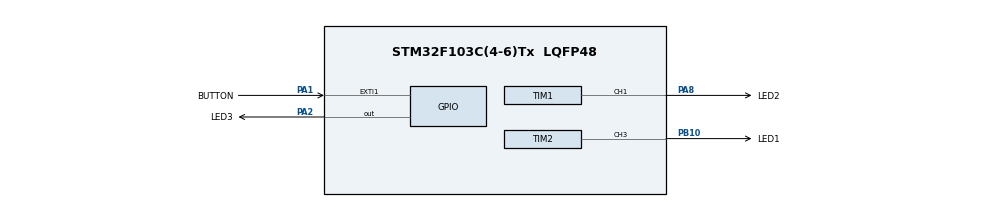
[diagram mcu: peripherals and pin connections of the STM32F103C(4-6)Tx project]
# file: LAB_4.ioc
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Mcu.Family=STM32F1
Mcu.Name=STM32F103C(4-6)Tx
Mcu.Package=LQFP48
NVIC.EXTI1_IRQn=true\:0\:0\:false\:true\:true\:1\:true\:true
NVIC.PriorityGroup=NVIC_PRIORITYGROUP_4
PA1.GPIO_Label=BUTTON
PA1.Signal=GPXTI1
PA2.GPIO_Label=LED3
PA2.Signal=GPIO_Output
PA8.GPIO_Label=LED2
PA8.Signal=S_TIM1_CH1
PB10.GPIO_Label=LED1
PB10.Signal=S_TIM2_CH3
ProjectManager.HeapSize=0x200
ProjectManager.StackSize=0x400
ProjectManager.TargetToolchain=STM32CubeIDE
RCC.APB1Freq_Value=8000000
RCC.APB2Freq_Value=8000000
SH.S_TIM1_CH1.0=TIM1_CH1,PWM Generation1 CH1
SH.S_TIM2_CH3.0=TIM2_CH3,PWM Generation3 CH3
TIM1.Channel-PWM\ Generation1\ CH1=TIM_CHANNEL_1
TIM1.ClockDivision=TIM_CLOCKDIVISION_DIV4
TIM1.Period=400
TIM1.Prescaler=8000
TIM1.Pulse-PWM\ Generation1\ CH1=200
TIM2.Channel-PWM\ Generation3\ CH3=TIM_CHANNEL_3
TIM2.ClockDivision=TIM_CLOCKDIVISION_DIV4
TIM2.Period=800
TIM2.Prescaler=8000
TIM2.Pulse-PWM\ Generation3\ CH3=200
VP_SYS_VS_ND.Mode=No_Debug
VP_TIM1_VS_ClockSourceINT.Mode=Internal
VP_TIM2_VS_ClockSourceINT.Mode=Internal
board=custom

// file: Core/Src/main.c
/* USER CODE BEGIN Header */
/**
  ******************************************************************************
  * @file           : main.c
  * @brief          : Main program body
  ******************************************************************************
  * @attention
  *
  * <h2><center>&copy; Copyright (c) 2021 STMicroelectronics.
  * All rights reserved.</center></h2>
  *
  * This software component is licensed by ST under BSD 3-Clause license,
  * the "License"; You may not use this file except in compliance with the
  * License. You may obtain a copy of the License at:
  *                        opensource.org/licenses/BSD-3-Clause
  *
  ******************************************************************************
  */
/* USER CODE END Header */
#include "main.h"

TIM_HandleTypeDef htim1;
TIM_HandleTypeDef htim2;

void SystemClock_Config(void);
static void MX_GPIO_Init(void);
static void MX_TIM1_Init(void);
static void MX_TIM2_Init(void);
static void MX_NVIC_Init(void);

int main(void)
{

  /* MCU Configuration--------------------------------------------------------*/

  /* Reset of all peripherals, Initializes the Flash interface and the Systick. */
  HAL_Init();

  /* Configure the system clock */
  SystemClock_Config();

  /* Initialize all configured peripherals */
  MX_GPIO_Init();
  MX_TIM1_Init();
  MX_TIM2_Init();

  /* Initialize interrupts */
  MX_NVIC_Init();
  /* USER CODE BEGIN 2 */
  HAL_TIM_PWM_Start(&htim1, TIM_CHANNEL_1);
  HAL_TIM_PWM_Start(&htim2, TIM_CHANNEL_3);
  /* USER CODE END 2 */

  /* Infinite loop */
  /* USER CODE BEGIN WHILE */
  while (1)
  {
	  HAL_GPIO_TogglePin(LED3_GPIO_Port, LED3_Pin);
	  HAL_Delay(300);
    /* USER CODE END WHILE */

  }
}

void SystemClock_Config(void)
{
  RCC_OscInitTypeDef RCC_OscInitStruct = {0};
  RCC_ClkInitTypeDef RCC_ClkInitStruct = {0};

  /** Initializes the RCC Oscillators according to the specified parameters
  * in the RCC_OscInitTypeDef structure.
  */
  RCC_OscInitStruct.OscillatorType = RCC_OSCILLATORTYPE_HSI;
  RCC_OscInitStruct.HSIState = RCC_HSI_ON;
  RCC_OscInitStruct.HSICalibrationValue = RCC_HSICALIBRATION_DEFAULT;
  RCC_OscInitStruct.PLL.PLLState = RCC_PLL_NONE;
  if (HAL_RCC_OscConfig(&RCC_OscInitStruct) != HAL_OK)
  {
    Error_Handler();
  }
  /** Initializes the CPU, AHB and APB buses clocks
  */
  RCC_ClkInitStruct.ClockType = RCC_CLOCKTYPE_HCLK|RCC_CLOCKTYPE_SYSCLK
                              |RCC_CLOCKTYPE_PCLK1|RCC_CLOCKTYPE_PCLK2;
  RCC_ClkInitStruct.SYSCLKSource = RCC_SYSCLKSOURCE_HSI;
  RCC_ClkInitStruct.AHBCLKDivider = RCC_SYSCLK_DIV1;
  RCC_ClkInitStruct.APB1CLKDivider = RCC_HCLK_DIV1;
  RCC_ClkInitStruct.APB2CLKDivider = RCC_HCLK_DIV1;

  if (HAL_RCC_ClockConfig(&RCC_ClkInitStruct, FLASH_LATENCY_0) != HAL_OK)
  {
    Error_Handler();
  }
}

/**
  * @brief NVIC Configuration.
  * @retval None
  */
static void MX_NVIC_Init(void)
{
  /* EXTI1_IRQn interrupt configuration */
  HAL_NVIC_SetPriority(EXTI1_IRQn, 0, 0);
  HAL_NVIC_EnableIRQ(EXTI1_IRQn);
}

static void MX_TIM1_Init(void)
{

  TIM_ClockConfigTypeDef sClockSourceConfig = {0};
  TIM_MasterConfigTypeDef sMasterConfig = {0};
  TIM_OC_InitTypeDef sConfigOC = {0};
  TIM_BreakDeadTimeConfigTypeDef sBreakDeadTimeConfig = {0};

  htim1.Instance = TIM1;
  htim1.Init.Prescaler = 8000;
  htim1.Init.CounterMode = TIM_COUNTERMODE_UP;
  htim1.Init.Period = 400;
  htim1.Init.ClockDivision = TIM_CLOCKDIVISION_DIV4;
  htim1.Init.RepetitionCounter = 0;
  htim1.Init.AutoReloadPreload = TIM_AUTORELOAD_PRELOAD_DISABLE;
  if (HAL_TIM_Base_Init(&htim1) != HAL_OK)
  {
    Error_Handler();
  }
  sClockSourceConfig.ClockSource = TIM_CLOCKSOURCE_INTERNAL;
  if (HAL_TIM_ConfigClockSource(&htim1, &sClockSourceConfig) != HAL_OK)
  {
    Error_Handler();
  }
  if (HAL_TIM_PWM_Init(&htim1) != HAL_OK)
  {
    Error_Handler();
  }
  sMasterConfig.MasterOutputTrigger = TIM_TRGO_RESET;
  sMasterConfig.MasterSlaveMode = TIM_MASTERSLAVEMODE_DISABLE;
  if (HAL_TIMEx_MasterConfigSynchronization(&htim1, &sMasterConfig) != HAL_OK)
  {
    Error_Handler();
  }
  sConfigOC.OCMode = TIM_OCMODE_PWM1;
  sConfigOC.Pulse = 200;
  sConfigOC.OCPolarity = TIM_OCPOLARITY_HIGH;
  sConfigOC.OCNPolarity = TIM_OCNPOLARITY_HIGH;
  sConfigOC.OCFastMode = TIM_OCFAST_DISABLE;
  sConfigOC.OCIdleState = TIM_OCIDLESTATE_RESET;
  sConfigOC.OCNIdleState = TIM_OCNIDLESTATE_RESET;
  if (HAL_TIM_PWM_ConfigChannel(&htim1, &sConfigOC, TIM_CHANNEL_1) != HAL_OK)
  {
    Error_Handler();
  }
  sBreakDeadTimeConfig.OffStateRunMode = TIM_OSSR_DISABLE;
  sBreakDeadTimeConfig.OffStateIDLEMode = TIM_OSSI_DISABLE;
  sBreakDeadTimeConfig.LockLevel = TIM_LOCKLEVEL_OFF;
  sBreakDeadTimeConfig.DeadTime = 0;
  sBreakDeadTimeConfig.BreakState = TIM_BREAK_DISABLE;
  sBreakDeadTimeConfig.BreakPolarity = TIM_BREAKPOLARITY_HIGH;
  sBreakDeadTimeConfig.AutomaticOutput = TIM_AUTOMATICOUTPUT_DISABLE;
  if (HAL_TIMEx_ConfigBreakDeadTime(&htim1, &sBreakDeadTimeConfig) != HAL_OK)
  {
    Error_Handler();
  }
  HAL_TIM_MspPostInit(&htim1);

}

static void MX_TIM2_Init(void)
{

  TIM_ClockConfigTypeDef sClockSourceConfig = {0};
  TIM_MasterConfigTypeDef sMasterConfig = {0};
  TIM_OC_InitTypeDef sConfigOC = {0};

  htim2.Instance = TIM2;
  htim2.Init.Prescaler = 8000;
  htim2.Init.CounterMode = TIM_COUNTERMODE_UP;
  htim2.Init.Period = 800;
  htim2.Init.ClockDivision = TIM_CLOCKDIVISION_DIV4;
  htim2.Init.AutoReloadPreload = TIM_AUTORELOAD_PRELOAD_DISABLE;
  if (HAL_TIM_Base_Init(&htim2) != HAL_OK)
  {
    Error_Handler();
  }
  sClockSourceConfig.ClockSource = TIM_CLOCKSOURCE_INTERNAL;
  if (HAL_TIM_ConfigClockSource(&htim2, &sClockSourceConfig) != HAL_OK)
  {
    Error_Handler();
  }
  if (HAL_TIM_PWM_Init(&htim2) != HAL_OK)
  {
    Error_Handler();
  }
  sMasterConfig.MasterOutputTrigger = TIM_TRGO_RESET;
  sMasterConfig.MasterSlaveMode = TIM_MASTERSLAVEMODE_DISABLE;
  if (HAL_TIMEx_MasterConfigSynchronization(&htim2, &sMasterConfig) != HAL_OK)
  {
    Error_Handler();
  }
  sConfigOC.OCMode = TIM_OCMODE_PWM1;
  sConfigOC.Pulse = 200;
  sConfigOC.OCPolarity = TIM_OCPOLARITY_HIGH;
  sConfigOC.OCFastMode = TIM_OCFAST_DISABLE;
  if (HAL_TIM_PWM_ConfigChannel(&htim2, &sConfigOC, TIM_CHANNEL_3) != HAL_OK)
  {
    Error_Handler();
  }
  HAL_TIM_MspPostInit(&htim2);

}

static void MX_GPIO_Init(void)
{
  GPIO_InitTypeDef GPIO_InitStruct = {0};

  /* GPIO Ports Clock Enable */
  __HAL_RCC_GPIOA_CLK_ENABLE();
  __HAL_RCC_GPIOB_CLK_ENABLE();

  /*Configure GPIO pin Output Level */
  HAL_GPIO_WritePin(LED3_GPIO_Port, LED3_Pin, GPIO_PIN_RESET);

  /*Configure GPIO pin : BUTTON_Pin */
  GPIO_InitStruct.Pin = BUTTON_Pin;
  GPIO_InitStruct.Mode = GPIO_MODE_IT_RISING;
  GPIO_InitStruct.Pull = GPIO_NOPULL;
  HAL_GPIO_Init(BUTTON_GPIO_Port, &GPIO_InitStruct);

  /*Configure GPIO pin : LED3_Pin */
  GPIO_InitStruct.Pin = LED3_Pin;
  GPIO_InitStruct.Mode = GPIO_MODE_OUTPUT_PP;
  GPIO_InitStruct.Pull = GPIO_NOPULL;
  GPIO_InitStruct.Speed = GPIO_SPEED_FREQ_LOW;
  HAL_GPIO_Init(LED3_GPIO_Port, &GPIO_InitStruct);

}

/* USER CODE BEGIN 4 */
void HAL_GPIO_EXTI_Callback(uint16_t GPIO_Pin)
{
	if(GPIO_Pin == BUTTON_Pin)
	{
		static int state = 0;
		state ^= 1;
		if(state == 0)
		{
			HAL_TIM_PWM_Start(&htim1, TIM_CHANNEL_1);
			HAL_TIM_PWM_Start(&htim2, TIM_CHANNEL_3);
		}
		else
		{
			HAL_TIM_PWM_Stop(&htim1, TIM_CHANNEL_1);
			HAL_TIM_PWM_Stop(&htim2, TIM_CHANNEL_3);
		}
	}
}
/* USER CODE END 4 */

void Error_Handler(void)
{
  __disable_irq();
  while (1)
  {
  }
}

/************************ (C) COPYRIGHT STMicroelectronics *****END OF FILE****/
